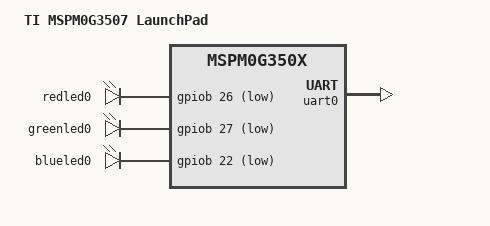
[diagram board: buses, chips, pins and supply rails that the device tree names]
/* SPDX-License-Identifier: Apache-2.0 */

/dts-v1/;

#include <ti/mspm0g3507.dtsi>

/ {
	model = "TI MSPM0G3507 LaunchPad";
	compatible = "ti,ti_mspm0g3507_launchpad","ti,mspm0g3507",
						"ti,mspm0g350x";

	chosen {
		zephyr,console = &uart0;
		zephyr,sram = &sram0;
		zephyr,flash = &flash0;
	};

    leds {
   		compatible = "gpio-leds";
   		redled0: red_led0 {
   			gpios = <&gpiob 26 GPIO_ACTIVE_LOW>;
        };
   		greenled0: green_led0 {
   			gpios = <&gpiob 27 GPIO_ACTIVE_LOW>;
        };
   		blueled0: blue_led0 {
   			gpios = <&gpiob 22 GPIO_ACTIVE_LOW>;
        };
    };

};

&cpu0 {
	clock-frequency = <32000000>;
};

&uart0 {
    status = "okay";
};

&gpioa {
	status = "okay";
};

&gpiob {
	status = "okay";
};

